# N32MC47x_DP47x register map
Vendor: Nsingtech Ltd.; File version: 1.0
Registers are 32-bit, read-write, reset 0x0 unless marked. A register's access mark holds for its fields unless they carry their own. Offsets are from the block's base; [hi:lo] are bit positions; {n}, {i} and the like mark numbered series; 'fields as' and 'values as' point back to an identical list.

## SHRTIM_TIME — Super high resolution timer: TIME
Base 0x40030280
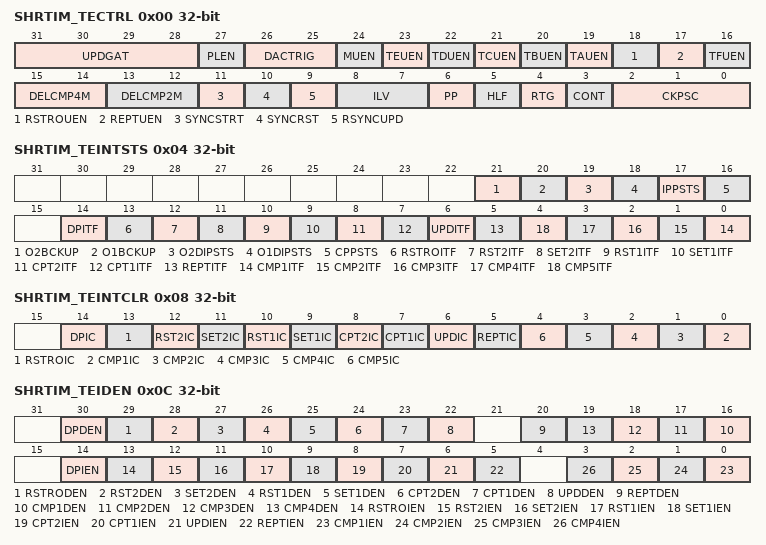
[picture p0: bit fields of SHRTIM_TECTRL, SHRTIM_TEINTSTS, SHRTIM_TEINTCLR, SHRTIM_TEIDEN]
0x00 SHRTIM_TECTRL
  [31:28] UPDGAT, [27] PLEN, [26:25] DACTRIG, [24] MUEN, [23] TEUEN, [22] TDUEN, [21] TCUEN, [20] TBUEN, [19] TAUEN, [18] RSTROUEN, [17] REPTUEN, [16] TFUEN, [15:14] DELCMP4M, [13:12] DELCMP2M, [11] SYNCSTRT, [10] SYNCRST, [9] RSYNCUPD, [8:7] ILV, [6] PP, [5] HLF, [4] RTG, [3] CONT, [2:0] CKPSC
0x04 SHRTIM_TEINTSTS ro
  [21] O2BCKUP, [20] O1BCKUP, [19] O2DIPSTS, [18] O1DIPSTS, [17] IPPSTS, [16] CPPSTS, [14] DPITF, [13] RSTROITF, [12] RST2ITF, [11] SET2ITF, [10] RST1ITF, [9] SET1ITF, [8] CPT2ITF, [7] CPT1ITF, [6] UPDITF, [5] REPTITF, [n-1] CMP{n}ITF (n=1..5)
0x08 SHRTIM_TEINTCLR wo
  [14] DPIC, [13] RSTROIC, [12] RST2IC, [11] SET2IC, [10] RST1IC, [9] SET1IC, [8] CPT2IC, [7] CPT1IC, [6] UPDIC, [5] REPTIC, [n-1] CMP{n}IC (n=1..5)
0x0C SHRTIM_TEIDEN
  [30] DPDEN, [29] RSTRODEN, [28] RST2DEN, [27] SET2DEN, [26] RST1DEN, [25] SET1DEN, [24] CPT2DEN, [23] CPT1DEN, [22] UPDDEN, [20] REPTDEN, [n+15] CMP{n}DEN (n=1..4), [14] DPIEN, [13] RSTROIEN, [12] RST2IEN, [11] SET2IEN, [10] RST1IEN, [9] SET1IEN, [8] CPT2IEN, [7] CPT1IEN, [6] UPDIEN, [5] REPTIEN, [n-1] CMP{n}IEN (n=1..4)
0x10 SHRTIM_TECNT
  [15:0] COUNT
0x14 SHRTIM_TEPRD reset 0xFFDF
  [15:0] PRD
0x18 SHRTIM_TEREPT
  [7:0] REPT
0x1C SHRTIM_TECMP1DAT
  [15:0] CMP1DAT
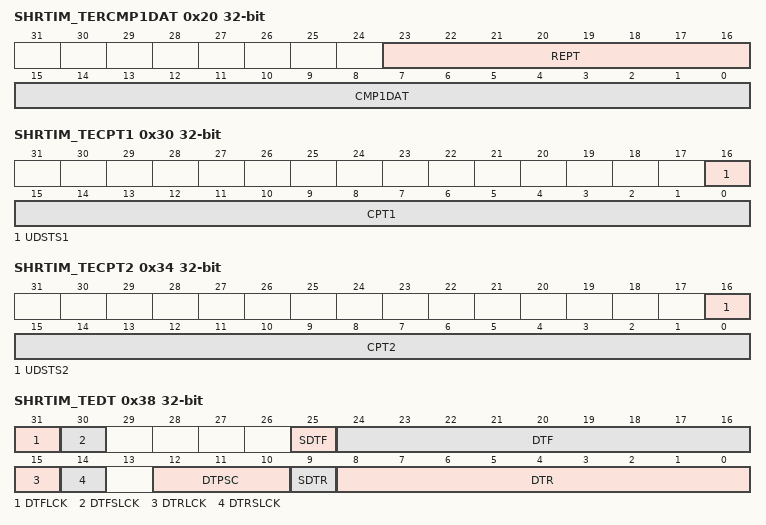
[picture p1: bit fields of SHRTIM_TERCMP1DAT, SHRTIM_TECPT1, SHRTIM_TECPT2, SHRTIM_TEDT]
0x20 SHRTIM_TERCMP1DAT
  [23:16] REPT, [15:0] CMP1DAT
{0x1C+4i} SHRTIM_TECMP{i}DAT (i=2..4)
  [15:0] CMP{i}DAT
0x30 SHRTIM_TECPT1
  [16] UDSTS1, [15:0] CPT1
0x34 SHRTIM_TECPT2
  [16] UDSTS2, [15:0] CPT2
0x38 SHRTIM_TEDT
  [31] DTFLCK, [30] DTFSLCK, [25] SDTF, [24:16] DTF, [15] DTRLCK, [14] DTRSLCK, [12:10] DTPSC, [9] SDTR, [8:0] DTR
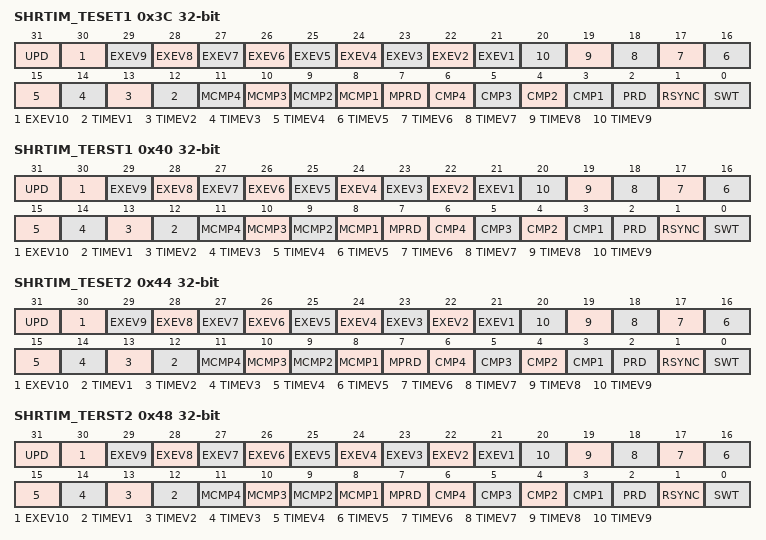
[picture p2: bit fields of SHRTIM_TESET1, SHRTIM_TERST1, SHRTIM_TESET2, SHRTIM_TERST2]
0x3C SHRTIM_TESET1
  [31] UPD, [n+20] EXEV{n} (n=1..10), [n+11] TIMEV{n} (n=1..9), [n+7] MCMP{n} (n=1..4), [7] MPRD, [n+2] CMP{n} (n=1..4), [2] PRD, [1] RSYNC, [0] SWT
0x40 SHRTIM_TERST1
  fields as SHRTIM_TESET1
0x44 SHRTIM_TESET2
  fields as SHRTIM_TESET1
0x48 SHRTIM_TERST2
  fields as SHRTIM_TESET1
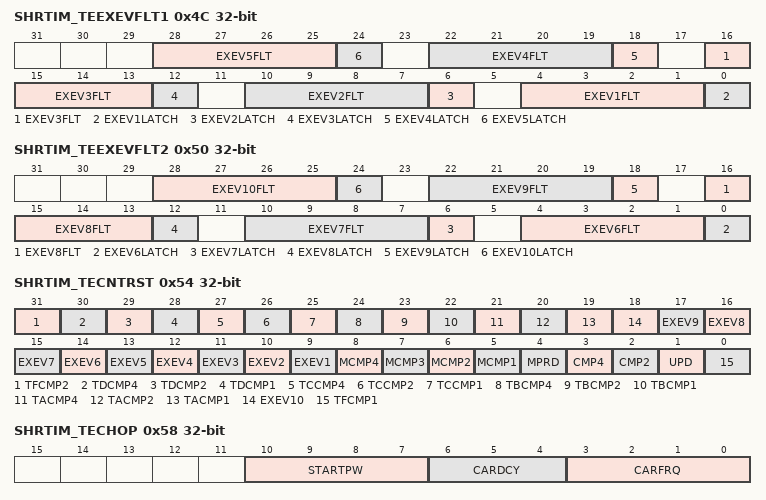
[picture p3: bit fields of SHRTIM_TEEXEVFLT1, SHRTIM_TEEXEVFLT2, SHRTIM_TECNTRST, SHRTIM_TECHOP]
0x4C SHRTIM_TEEXEVFLT1
  [6n-2:6n-5] EXEV{n}FLT (n=1..5), [6n-6] EXEV{n}LATCH (n=1..5)
0x50 SHRTIM_TEEXEVFLT2
  [6n-32:6n-35] EXEV{n}FLT (n=6..10), [6n-36] EXEV{n}LATCH (n=6..10)
0x54 SHRTIM_TECNTRST
  [31] TFCMP2, [30] TDCMP4, [29] TDCMP2, [28] TDCMP1, [27] TCCMP4, [26] TCCMP2, [25] TCCMP1, [24] TBCMP4, [23] TBCMP2, [22] TBCMP1, [21] TACMP4, [20] TACMP2, [19] TACMP1, [n+8] EXEV{n} (n=1..10), [n+4] MCMP{n} (n=1..4), [4] MPRD, [3] CMP4, [2] CMP2, [1] UPD, [0] TFCMP1
0x58 SHRTIM_TECHOP
  [10:7] STARTPW, [6:4] CARDCY, [3:0] CARFRQ
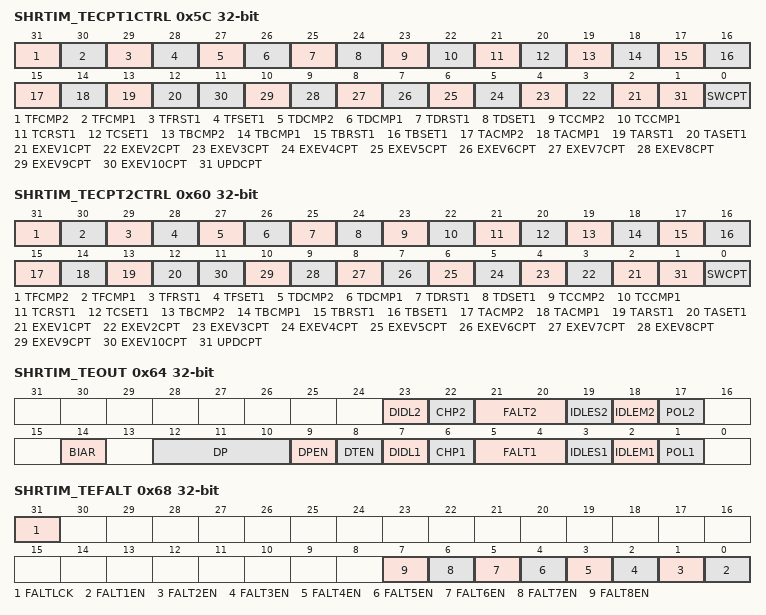
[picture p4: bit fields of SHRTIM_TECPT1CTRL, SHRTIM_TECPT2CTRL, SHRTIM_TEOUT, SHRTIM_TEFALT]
0x5C SHRTIM_TECPT1CTRL
  [31] TFCMP2, [30] TFCMP1, [29] TFRST1, [28] TFSET1, [27] TDCMP2, [26] TDCMP1, [25] TDRST1, [24] TDSET1, [23] TCCMP2, [22] TCCMP1, [21] TCRST1, [20] TCSET1, [19] TBCMP2, [18] TBCMP1, [17] TBRST1, [16] TBSET1, [15] TACMP2, [14] TACMP1, [13] TARST1, [12] TASET1, [n+1] EXEV{n}CPT (n=1..10), [1] UPDCPT, [0] SWCPT
0x60 SHRTIM_TECPT2CTRL
  fields as SHRTIM_TECPT1CTRL
0x64 SHRTIM_TEOUT
  [23] DIDL2, [22] CHP2, [21:20] FALT2, [19] IDLES2, [18] IDLEM2, [17] POL2, [14] BIAR, [12:10] DP, [9] DPEN, [8] DTEN, [7] DIDL1, [6] CHP1, [5:4] FALT1, [3] IDLES1, [2] IDLEM1, [1] POL1
0x68 SHRTIM_TEFALT
  [31] FALTLCK, [n-1] FALT{n}EN (n=1..8)
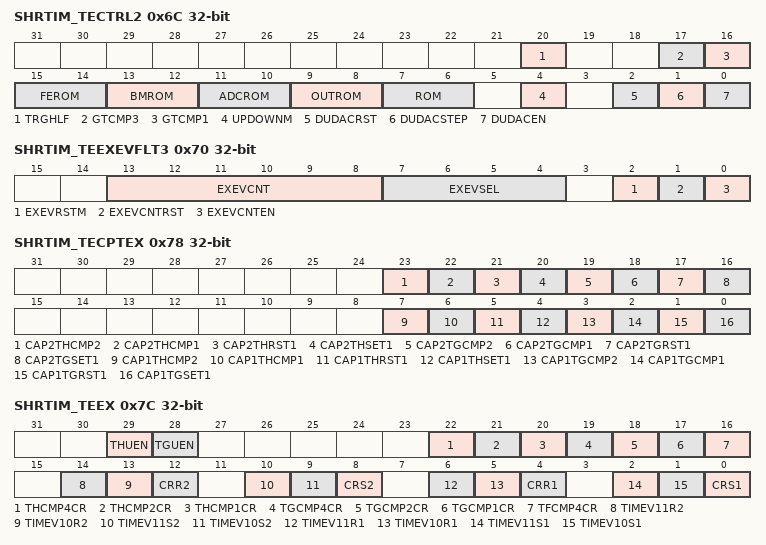
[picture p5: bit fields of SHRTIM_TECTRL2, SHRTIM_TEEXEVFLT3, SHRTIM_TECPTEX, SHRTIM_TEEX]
0x6C SHRTIM_TECTRL2
  [20] TRGHLF, [17] GTCMP3, [16] GTCMP1, [15:14] FEROM, [13:12] BMROM, [11:10] ADCROM, [9:8] OUTROM, [7:6] ROM, [4] UPDOWNM, [2] DUDACRST, [1] DUDACSTEP, [0] DUDACEN
0x70 SHRTIM_TEEXEVFLT3
  [13:8] EXEVCNT, [7:4] EXEVSEL, [2] EXEVRSTM, [1] EXEVCNTRST, [0] EXEVCNTEN
0x74 SHRTIM_TECMP5DAT
  [15:0] CMP5DAT
0x78 SHRTIM_TECPTEX
  [23] CAP2THCMP2, [22] CAP2THCMP1, [21] CAP2THRST1, [20] CAP2THSET1, [19] CAP2TGCMP2, [18] CAP2TGCMP1, [17] CAP2TGRST1, [16] CAP2TGSET1, [7] CAP1THCMP2, [6] CAP1THCMP1, [5] CAP1THRST1, [4] CAP1THSET1, [3] CAP1TGCMP2, [2] CAP1TGCMP1, [1] CAP1TGRST1, [0] CAP1TGSET1
0x7C SHRTIM_TEEX
  [29] THUEN, [28] TGUEN, [22] THCMP4CR, [21] THCMP2CR, [20] THCMP1CR, [19] TGCMP4CR, [18] TGCMP2CR, [17] TGCMP1CR, [16] TFCMP4CR, [14] TIMEV11R2, [13] TIMEV10R2, [12] CRR2, [10] TIMEV11S2, [9] TIMEV10S2, [8] CRS2, [6] TIMEV11R1, [5] TIMEV10R1, [4] CRR1, [2] TIMEV11S1, [1] TIMEV10S1, [0] CRS1
